# EFM32GG12B410F1024IL112 register map
File version: 3.0.0
CPU: CM4 r0p1, little endian, MPU, FPU, 3 interrupt priority bits
Registers are 32-bit, read-write, reset 0x0 unless marked. A register's access mark holds for its fields unless they carry their own. Offsets are from the block's base; [hi:lo] are bit positions; {n}, {i} and the like mark numbered series; 'fields as' and 'values as' point back to an identical list.

## ADC0
Base 0x40082000
Same registers: ADC1 0x40082400
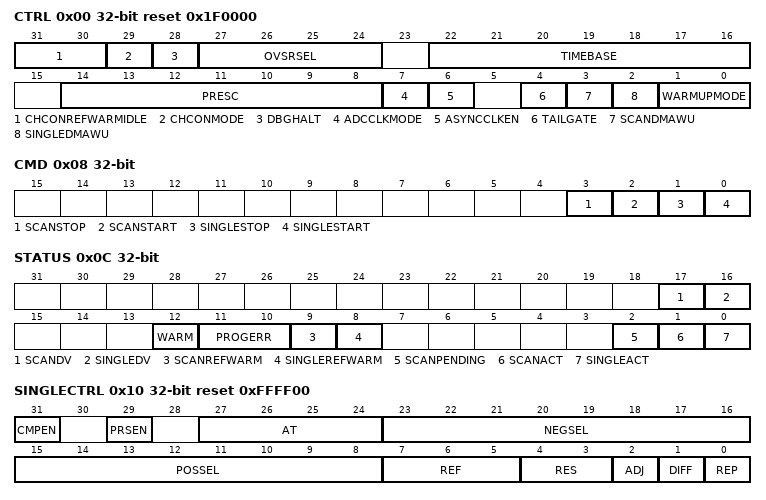
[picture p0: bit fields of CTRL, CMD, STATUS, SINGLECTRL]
0x00 CTRL reset 0x1F0000 — Control Register
  [31:30] CHCONREFWARMIDLE — Channel Connect and Reference Warm Sel When ADC is IDLE
    0=PREFSCAN (Keep scan reference warm and APORT switches for first scan channel closed if WARMUPMODE is not NORMAL); 1=PREFSINGLE (Keep single reference warm and keep APORT switches for single channel closed if WARMUPMODE is not NORMAL); 2=KEEPPREV (Keep last used reference warm and keep APORT switches for corresponding channel closed if WARMUPMODE is not NORMAL)
  [29] CHCONMODE — Channel Connect
  [28] DBGHALT — Debug Mode Halt Enable
  [27:24] OVSRSEL — Oversample Rate Select
    0=X2 (2 samples for each conversion result); 1=X4 (4 samples for each conversion result); 2=X8 (8 samples for each conversion result); 3=X16 (16 samples for each conversion result); 4=X32 (32 samples for each conversion result); 5=X64 (64 samples for each conversion result); 6=X128 (128 samples for each conversion result); 7=X256 (256 samples for each conversion result); 8=X512 (512 samples for each conversion result); 9=X1024 (1024 samples for each conversion result); 10=X2048 (2048 samples for each conversion result); 11=X4096 (4096 samples for each conversion result)
  [22:16] TIMEBASE — 1us Time Base
  [14:8] PRESC — Prescalar Setting for ADC Sample and Conversion Clock
    0=NODIVISION
  [7] ADCCLKMODE — ADC Clock Mode
  [6] ASYNCCLKEN — Selects ASYNC CLK Enable Mode When ADCCLKMODE=1
  [4] TAILGATE — Conversion Tailgating
  [3] SCANDMAWU — SCANFIFO DMA Wakeup
  [2] SINGLEDMAWU — SINGLEFIFO DMA Wakeup
  [1:0] WARMUPMODE
    0=NORMAL (ADC is shut down after each conversion. 5us warmup time is used before each conversion.); 1=KEEPINSTANDBY (ADC is kept in standby mode between conversions. 1us warmup time is used before each conversion.); 2=KEEPINSLOWACC (ADC is kept in slow acquisition mode between conversions. 1us warmup time is used before each conversion.); 3=KEEPADCWARM (ADC is kept on after conversions, allowing for continuous conversion.)
0x08 CMD wo — Command Register
  [3] SCANSTOP — Scan Sequence Stop
  [2] SCANSTART — Scan Sequence Start
  [1] SINGLESTOP — Single Channel Conversion Stop
  [0] SINGLESTART — Single Channel Conversion Start
0x0C STATUS ro
  [17] SCANDV — Scan Data Valid
  [16] SINGLEDV — Single Channel Data Valid
  [12] WARM — ADC Warmed Up
  [11:10] PROGERR — Programming Error Status
    1=BUSCONF; 2=NEGSELCONF
  [9] SCANREFWARM — Scan Reference Warmed Up
  [8] SINGLEREFWARM — Single Channel Reference Warmed Up
  [2] SCANPENDING — Scan Conversion Pending
  [1] SCANACT — Scan Conversion Active
  [0] SINGLEACT — Single Channel Conversion Active
0x10 SINGLECTRL reset 0xFFFF00 — Single Channel Control Register
  [31] CMPEN — Compare Logic Enable for Single Channel
  [29] PRSEN — Single Channel PRS Trigger Enable
  [27:24] AT — Single Channel Acquisition Time
    0=1CYCLE (1 conversion clock cycle acquisition time for single channel); 1=2CYCLES (2 conversion clock cycles acquisition time for single channel); 2=3CYCLES (3 conversion clock cycles acquisition time for single channel); 3=4CYCLES (4 conversion clock cycles acquisition time for single channel); 4=8CYCLES (8 conversion clock cycles acquisition time for single channel); 5=16CYCLES (16 conversion clock cycles acquisition time for single channel); 6=32CYCLES (32 conversion clock cycles acquisition time for single channel); 7=64CYCLES (64 conversion clock cycles acquisition time for single channel); 8=128CYCLES (128 conversion clock cycles acquisition time for single channel); 9=256CYCLES (256 conversion clock cycles acquisition time for single channel)
  [23:16] NEGSEL — Single Channel Negative Input Selection
  [15:8] POSSEL — Single Channel Positive Input Selection
  [7:5] REF — Single Channel Reference Selection
    0=1V25 (VFS = 1.25V with internal VBGR reference); 1=2V5 (VFS = 2.5V with internal VBGR reference); 2=VDD (VFS = AVDD with AVDD as reference source); 3=5V (VFS = 5V with internal VBGR reference); 4=EXTSINGLE (Single ended external reference); 5=2XEXTDIFF (Differential external reference, 2x); 6=2XVDD (VFS = 2xAVDD with AVDD as the reference source); 7=CONF (Use SINGLECTRLX to configure reference)
  [4:3] RES — Single Channel Resolution Select
    0=12BIT (12-bit resolution.); 1=8BIT (8-bit resolution.); 2=6BIT (6-bit resolution.); 3=OVS (Oversampling enabled. Oversampling rate is set in OVSRSEL.)
  [2] ADJ — Single Channel Result Adjustment
  [1] DIFF — Single Channel Differential Mode
  [0] REP — Single Channel Repetitive Mode
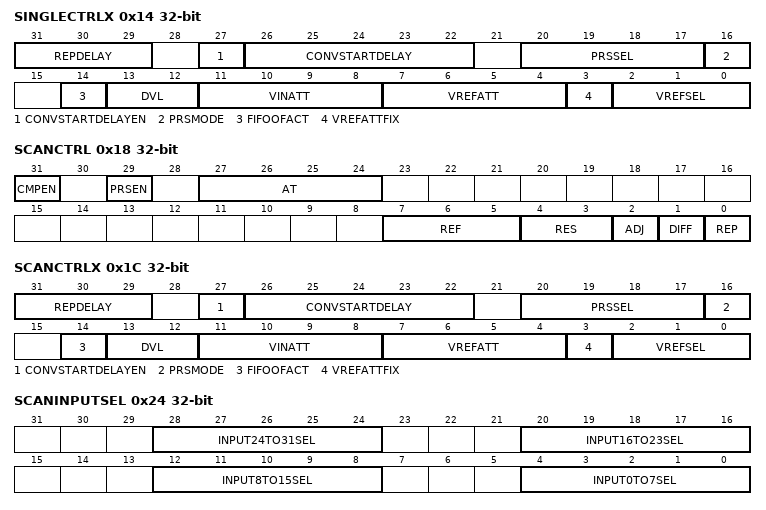
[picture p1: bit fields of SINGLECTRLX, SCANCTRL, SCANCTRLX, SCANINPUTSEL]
0x14 SINGLECTRLX — Single Channel Control Register Continued
  [31:29] REPDELAY — REPDELAY Select for SINGLE REP Mode
    0=NODELAY; 1=4CYCLES (4 conversion clock cycles); 2=8CYCLES (8 conversion clock cycles); 3=16CYCLES (16 conversion clock cycles); 4=32CYCLES (32 conversion clock cycles); 5=64CYCLES (64 conversion clock cycles); 6=128CYCLES (128 conversion clock cycles); 7=256CYCLES (256 conversion clock cycles)
  [27] CONVSTARTDELAYEN — Enable Delaying Next Conversion Start
  [26:22] CONVSTARTDELAY — Delay Value for Next Conversion Start If CONVSTARTDELAYEN is Set
  [20:17] PRSSEL — Single Channel PRS Trigger Select
    {v}=PRSCH{v} (PRS ch {v} triggers single channel) (v=0..15)
  [16] PRSMODE — Single Channel PRS Trigger Mode
  [14] FIFOOFACT — Single Channel FIFO Overflow Action
  [13:12] DVL — Single Channel DV Level Select
  [11:8] VINATT — Code for VIN Attenuation Factor
  [7:4] VREFATT — Code for VREF Attenuation Factor When VREFSEL is 1, 2 or 5
  [3] VREFATTFIX — Enable Fixed Scaling on VREF
  [2:0] VREFSEL — Single Channel Reference Selection
    0=VBGR (Internal 0.83V Bandgap reference); 1=VDDXWATT (Scaled AVDD: AVDD*(the VREF attenuation factor)); 2=VREFPWATT (Scaled singled ended external Vref: ADCn_EXTP*(the VREF attenuation factor)); 3=VREFP (Raw single ended external Vref: ADCn_EXTP); 4=VENTROPY (Special mode used to generate ENTROPY.); 5=VREFPNWATT (Scaled differential external Vref from : (ADCn_EXTP-ADCn_EXTN)*(the VREF attenuation factor)); 6=VREFPN (Raw differential external Vref from : (ADCn_EXTP-ADCn_EXTN)); 7=VBGRLOW (Internal Bandgap reference at low setting 0.78V)
0x18 SCANCTRL — Scan Control Register
  [31] CMPEN — Compare Logic Enable for Scan
  [29] PRSEN — Scan Sequence PRS Trigger Enable
  [27:24] AT — Scan Acquisition Time
    0=1CYCLE (1 conversion clock cycle acquisition time for scan); 1=2CYCLES (2 conversion clock cycles acquisition time for scan); 2=3CYCLES (3 conversion clock cycles acquisition time for scan); 3=4CYCLES (4 conversion clock cycles acquisition time for scan); 4=8CYCLES (8 conversion clock cycles acquisition time for scan); 5=16CYCLES (16 conversion clock cycles acquisition time for scan); 6=32CYCLES (32 conversion clock cycles acquisition time for scan); 7=64CYCLES (64 conversion clock cycles acquisition time for scan); 8=128CYCLES (128 conversion clock cycles acquisition time for scan); 9=256CYCLES (256 conversion clock cycles acquisition time for scan)
  [7:5] REF — Scan Sequence Reference Selection
    0=1V25 (VFS = 1.25V with internal VBGR reference); 1=2V5 (VFS = 2.5V with internal VBGR reference); 2=VDD (VFS = AVDD with AVDD as reference source); 3=5V (VFS = 5V with internal VBGR reference); 4=EXTSINGLE (Single ended external reference); 5=2XEXTDIFF (Differential external reference, 2x); 6=2XVDD (VFS=2xAVDD with AVDD as the reference source); 7=CONF (Use SCANCTRLX to configure reference)
  [4:3] RES — Scan Sequence Resolution Select
    0=12BIT (12-bit resolution); 1=8BIT (8-bit resolution); 2=6BIT (6-bit resolution); 3=OVS (Oversampling enabled. Oversampling rate is set in OVSRSEL)
  [2] ADJ — Scan Sequence Result Adjustment
  [1] DIFF — Scan Sequence Differential Mode
  [0] REP — Scan Sequence Repetitive Mode
0x1C SCANCTRLX — Scan Control Register Continued
  [31:29] REPDELAY — REPDELAY Select for SCAN REP Mode
    values as SINGLECTRLX.REPDELAY
  [27] CONVSTARTDELAYEN — Enable Delaying Next Conversion Start
  [26:22] CONVSTARTDELAY — Delay Next Conversion Start If CONVSTARTDELAYEN is Set
  [20:17] PRSSEL — Scan Sequence PRS Trigger Select
    {v}=PRSCH{v} (PRS ch {v} triggers scan sequence) (v=0..15)
  [16] PRSMODE — Scan PRS Trigger Mode
  [14] FIFOOFACT — Scan FIFO Overflow Action
  [13:12] DVL — Scan DV Level Select
  [11:8] VINATT — Code for VIN Attenuation Factor
  [7:4] VREFATT — Code for VREF Attenuation Factor When VREFSEL is 1, 2 or 5
  [3] VREFATTFIX — Enable Fixed Scaling on VREF
  [2:0] VREFSEL — Scan Channel Reference Selection
    0=VBGR (Internal 0.83V Bandgap reference); 1=VDDXWATT (Scaled AVDD: AVDD*(the VREF attenuation factor)); 2=VREFPWATT (Scaled singled ended external Vref: ADCn_EXTP*(the VREF attenuation factor)); 3=VREFP (Raw single ended external Vref: ADCn_EXTP); 5=VREFPNWATT (Scaled differential external Vref from : (ADCn_EXTP-ADCn_EXTN)*(the VREF attenuation factor)); 6=VREFPN (Raw differential external Vref from : (ADCn_EXTP-ADCn_EXTN)); 7=VBGRLOW (Internal Bandgap reference at low setting 0.78V)
0x20 SCANMASK — Scan Sequence Input Mask Register
  [31:0] SCANINPUTEN — Scan Sequence Input Mask
0x24 SCANINPUTSEL — Input Selection Register for Scan Mode
  [all] fields
    0=APORT0CH0TO7; 1=APORT0CH8TO15; 4=APORT1CH0TO7; 5=APORT1CH8TO15; 6=APORT1CH16TO23; 7=APORT1CH24TO31; 8=APORT2CH0TO7; 9=APORT2CH8TO15; 10=APORT2CH16TO23; 11=APORT2CH24TO31; 12=APORT3CH0TO7; 13=APORT3CH8TO15; 14=APORT3CH16TO23; 15=APORT3CH24TO31; 16=APORT4CH0TO7; 17=APORT4CH8TO15; 18=APORT4CH16TO23; 19=APORT4CH24TO31
  [28:24] INPUT24TO31SEL — Inputs Chosen for ADCn_INPUT24-ADCn_INPUT31 as Referred in SCANMASK
  [20:16] INPUT16TO23SEL — Inputs Chosen for ADCn_INPUT16-ADCn_INPUT23 as Referred in SCANMASK
  [12:8] INPUT8TO15SEL — Inputs Chosen for ADCn_INPUT8-ADCn_INPUT15 as Referred in SCANMASK
  [4:0] INPUT0TO7SEL — Inputs Chosen for ADCn_INPUT7-ADCn_INPUT0 as Referred in SCANMASK
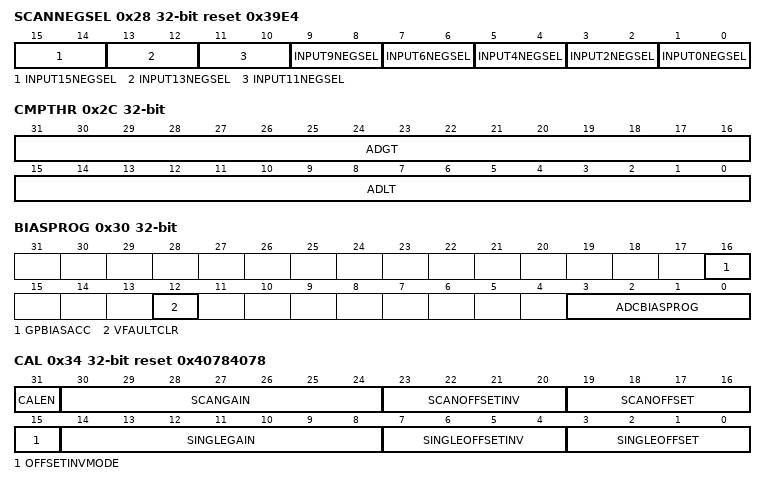
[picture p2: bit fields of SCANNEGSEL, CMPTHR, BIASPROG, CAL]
0x28 SCANNEGSEL reset 0x39E4 — Negative Input Select Register for Scan
  [15:14] INPUT15NEGSEL — Negative Input Select Register for ADCn_INPUT15 in Differential Scan Mode
    0=INPUT8 (Selects ADCn_INPUT8 as negative channel input); 1=INPUT10 (Selects ADCn_INPUT10 as negative channel input); 2=INPUT12 (Selects ADCn_INPUT12 as negative channel input); 3=INPUT14 (Selects ADCn_INPUT14 as negative channel input)
  [13:12] INPUT13NEGSEL — Negative Input Select Register for ADCn_INPUT13 in Differential Scan Mode
    values as INPUT15NEGSEL
  [11:10] INPUT11NEGSEL — Negative Input Select Register for ADCn_INPUT11 in Differential Scan Mode
    values as INPUT15NEGSEL
  [9:8] INPUT9NEGSEL — Negative Input Select Register for ADCn_INPUT9 in Differential Scan Mode
    values as INPUT15NEGSEL
  [7:6] INPUT6NEGSEL — Negative Input Select Register for ADCn_INPUT1 in Differential Scan Mode
    0=INPUT1 (Selects ADCn_INPUT1 as negative channel input); 1=INPUT3 (Selects ADCn_INPUT3 as negative channel input); 2=INPUT5 (Selects ADCn_INPUT5 as negative channel input); 3=INPUT7 (Selects ADCn_INPUT7 as negative channel input)
  [5:4] INPUT4NEGSEL — Negative Input Select Register for ADCn_INPUT4 in Differential Scan Mode
    values as INPUT6NEGSEL
  [3:2] INPUT2NEGSEL — Negative Input Select Register for ADCn_INPUT2 in Differential Scan Mode
    values as INPUT6NEGSEL
  [1:0] INPUT0NEGSEL — Negative Input Select Register for ADCn_INPUT0 in Differential Scan Mode
    values as INPUT6NEGSEL
0x2C CMPTHR — Compare Threshold Register
  [31:16] ADGT — Greater Than Compare Threshold
  [15:0] ADLT — Less Than Compare Threshold
0x30 BIASPROG — Bias Programming Register for Various Analog Blocks Used in ADC Operation
  [16] GPBIASACC — Accuracy Setting for the System Bias During ADC Operation
  [12] VFAULTCLR — Clear VREFOF Flag
  [3:0] ADCBIASPROG — Bias Programming Value of Analog ADC Block
    0=NORMAL (Normal power (use for 1Msps operation)); 4=SCALE2 (Scaling bias to 1/2); 8=SCALE4 (Scaling bias to 1/4); 12=SCALE8 (Scaling bias to 1/8); 14=SCALE16 (Scaling bias to 1/16); 15=SCALE32 (Scaling bias to 1/32)
0x34 CAL reset 0x40784078 — Calibration Register
  [31] CALEN — Calibration Mode is Enabled
  [30:24] SCANGAIN — Scan Mode Gain Calibration Value
  [23:20] SCANOFFSETINV — Scan Mode Offset Calibration Value for Negative Single-ended Mode
  [19:16] SCANOFFSET — Scan Mode Offset Calibration Value for Differential or Positive Single-ended Mode
  [15] OFFSETINVMODE — Negative Single-ended Offset Calibration is Enabled
  [14:8] SINGLEGAIN — Single Mode Gain Calibration Value
  [7:4] SINGLEOFFSETINV — Single Mode Offset Calibration Value for Negative Single-ended Mode
  [3:0] SINGLEOFFSET — Single Mode Offset Calibration Value for Differential or Positive Single-ended Mode
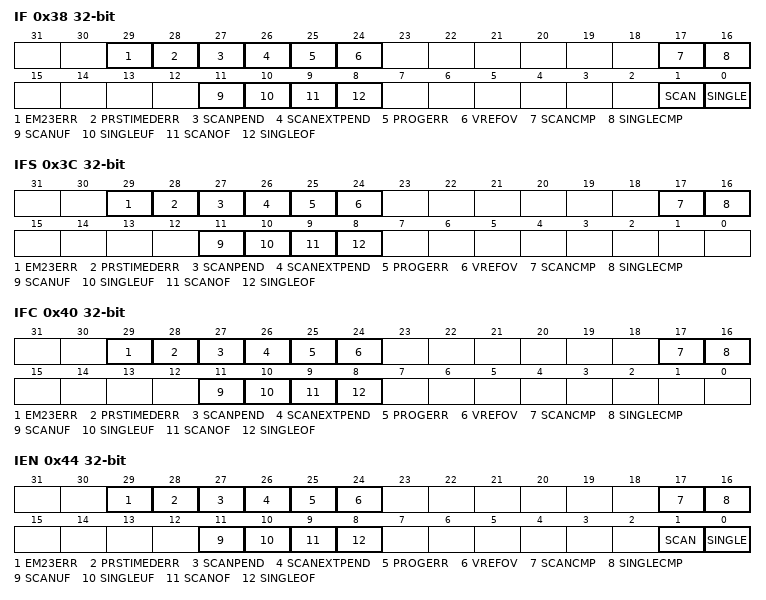
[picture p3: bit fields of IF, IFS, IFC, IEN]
0x38 IF ro — Interrupt Flag Register
  [29] EM23ERR — EM23 Entry Error Flag
  [28] PRSTIMEDERR — PRS Timed Mode Error Flag
  [27] SCANPEND — Scan Trigger Pending Flag
  [26] SCANEXTPEND — External Scan Trigger Pending Flag
  [25] PROGERR — Programming Error Interrupt Flag
  [24] VREFOV — VREF Over Voltage Interrupt Flag
  [17] SCANCMP — Scan Result Compare Match Interrupt Flag
  [16] SINGLECMP — Single Result Compare Match Interrupt Flag
  [11] SCANUF — Scan FIFO Underflow Interrupt Flag
  [10] SINGLEUF — Single FIFO Underflow Interrupt Flag
  [9] SCANOF — Scan FIFO Overflow Interrupt Flag
  [8] SINGLEOF — Single FIFO Overflow Interrupt Flag
  [1] SCAN — Scan Conversion Complete Interrupt Flag
  [0] SINGLE — Single Conversion Complete Interrupt Flag
0x3C IFS wo — Interrupt Flag Set Register
  [29] EM23ERR — Set EM23ERR Interrupt Flag
  [28] PRSTIMEDERR — Set PRSTIMEDERR Interrupt Flag
  [27] SCANPEND — Set SCANPEND Interrupt Flag
  [26] SCANEXTPEND — Set SCANEXTPEND Interrupt Flag
  [25] PROGERR — Set PROGERR Interrupt Flag
  [24] VREFOV — Set VREFOV Interrupt Flag
  [17] SCANCMP — Set SCANCMP Interrupt Flag
  [16] SINGLECMP — Set SINGLECMP Interrupt Flag
  [11] SCANUF — Set SCANUF Interrupt Flag
  [10] SINGLEUF — Set SINGLEUF Interrupt Flag
  [9] SCANOF — Set SCANOF Interrupt Flag
  [8] SINGLEOF — Set SINGLEOF Interrupt Flag
0x40 IFC wo — Interrupt Flag Clear Register
  [29] EM23ERR — Clear EM23ERR Interrupt Flag
  [28] PRSTIMEDERR — Clear PRSTIMEDERR Interrupt Flag
  [27] SCANPEND — Clear SCANPEND Interrupt Flag
  [26] SCANEXTPEND — Clear SCANEXTPEND Interrupt Flag
  [25] PROGERR — Clear PROGERR Interrupt Flag
  [24] VREFOV — Clear VREFOV Interrupt Flag
  [17] SCANCMP — Clear SCANCMP Interrupt Flag
  [16] SINGLECMP — Clear SINGLECMP Interrupt Flag
  [11] SCANUF — Clear SCANUF Interrupt Flag
  [10] SINGLEUF — Clear SINGLEUF Interrupt Flag
  [9] SCANOF — Clear SCANOF Interrupt Flag
  [8] SINGLEOF — Clear SINGLEOF Interrupt Flag
0x44 IEN — Interrupt Enable Register
  [29] EM23ERR — EM23ERR Interrupt Enable
  [28] PRSTIMEDERR — PRSTIMEDERR Interrupt Enable
  [27] SCANPEND — SCANPEND Interrupt Enable
  [26] SCANEXTPEND — SCANEXTPEND Interrupt Enable
  [25] PROGERR — PROGERR Interrupt Enable
  [24] VREFOV — VREFOV Interrupt Enable
  [17] SCANCMP — SCANCMP Interrupt Enable
  [16] SINGLECMP — SINGLECMP Interrupt Enable
  [11] SCANUF — SCANUF Interrupt Enable
  [10] SINGLEUF — SINGLEUF Interrupt Enable
  [9] SCANOF — SCANOF Interrupt Enable
  [8] SINGLEOF — SINGLEOF Interrupt Enable
  [1] SCAN — SCAN Interrupt Enable
  [0] SINGLE — SINGLE Interrupt Enable
0x48 SINGLEDATA ro read-has-side-effects — Single Conversion Result Data
  [31:0] DATA
0x4C SCANDATA ro read-has-side-effects — Scan Conversion Result Data
  [31:0] DATA
0x50 SINGLEDATAP ro — Single Conversion Result Data Peek Register
  [31:0] DATAP — Single Conversion Result Data Peek
0x54 SCANDATAP ro — Scan Sequence Result Data Peek Register
  [31:0] DATAP — Scan Conversion Result Data Peek
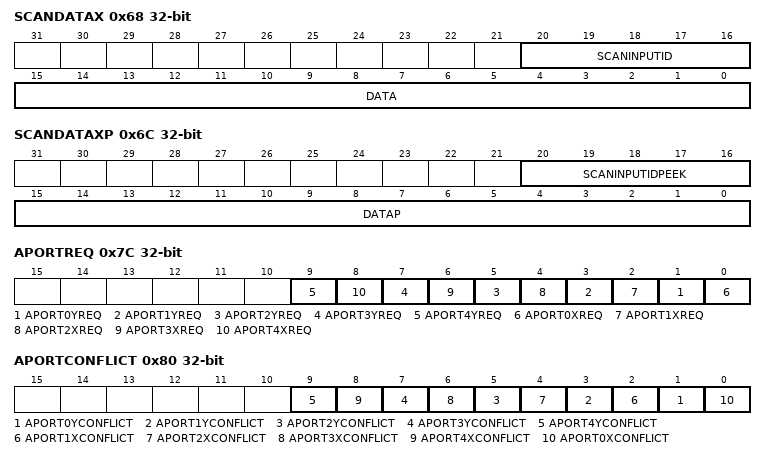
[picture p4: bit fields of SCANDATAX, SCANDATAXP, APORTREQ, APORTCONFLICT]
0x68 SCANDATAX ro read-has-side-effects — Scan Sequence Result Data + Data Source Register
  [20:16] SCANINPUTID — Scan Conversion Input ID
  [15:0] DATA — Scan Conversion Result Data
0x6C SCANDATAXP ro — Scan Sequence Result Data + Data Source Peek Register
  [20:16] SCANINPUTIDPEEK — Scan Conversion Data Source Peek
  [15:0] DATAP — Scan Conversion Result Data Peek
0x7C APORTREQ ro — APORT Request Status Register
  [2n+1] APORT{n}YREQ (n=0..4) — 1 If the Bus Connected to APORT{n}Y is Requested
  [2n] APORT{n}XREQ (n=0..4) — 1 If the Bus Connected to APORT{n}X is Requested
0x80 APORTCONFLICT ro — APORT Conflict Status Register
  [2n+1] APORT{n}YCONFLICT (n=0..4) — 1 If the Bus Connected to APORT{n}Y is in Conflict With Another Peripheral
  [2n] APORT{n}XCONFLICT (n=1..4) — 1 If the Bus Connected to APORT{n}X is in Conflict With Another Peripheral
  [0] APORT0XCONFLICT — 1 If the Bus Connected to APORT0X is in Conflict With Another Peripheral
0x84 SINGLEFIFOCOUNT ro
  [2:0] SINGLEDC — Single Data Count
0x88 SCANFIFOCOUNT ro
  [2:0] SCANDC — Scan Data Count
0x8C SINGLEFIFOCLEAR wo
  [0] SINGLEFIFOCLEAR — Clear Single FIFO Content
0x90 SCANFIFOCLEAR wo
  [0] SCANFIFOCLEAR — Clear Scan FIFO Content
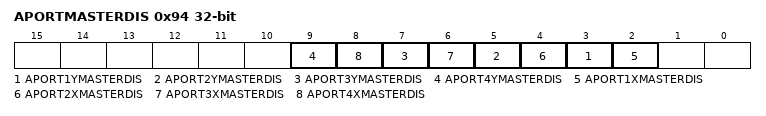
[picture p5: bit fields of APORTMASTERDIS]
0x94 APORTMASTERDIS — APORT Bus Master Disable Register
  [2n+1] APORT{n}YMASTERDIS (n=1..4) — APORT{n}Y Master Disable
  [2n] APORT{n}XMASTERDIS (n=1..4) — APORT{n}X Master Disable

## Notices in the file
# License
Copyright 2020 Silicon Laboratories Inc. www.silabs.com
SPDX-License-Identifier: Zlib
The licensor of this software is Silicon Laboratories Inc.
This software is provided 'as-is', without any express or implied
warranty. In no event will the authors be held liable for any damages
arising from the use of this software.
Permission is granted to anyone to use this software for any purpose,
including commercial applications, and to alter it and redistribute it
freely, subject to the following restrictions:
1. The origin of this software must not be misrepresented; you must not
claim that you wrote the original software. If you use this software
in a product, an acknowledgment in the product documentation would be
appreciated but is not required.
2. Altered source versions must be plainly marked as such, and must not be
misrepresented as being the original software.
3. This notice may not be removed or altered from any source distribution.
